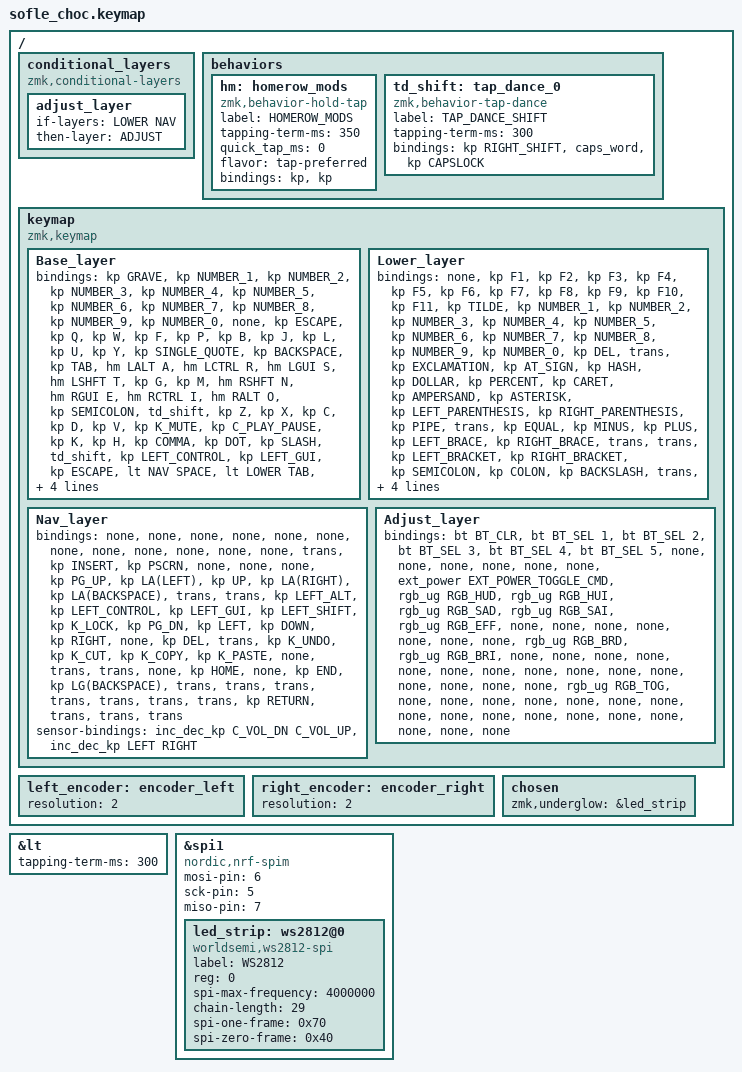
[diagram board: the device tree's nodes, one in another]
/*
 * Copyright (c) 2020 The ZMK Contributors
 *
 * SPDX-License-Identifier: MIT
 */

#include <behaviors.dtsi>
#include <dt-bindings/zmk/keys.h>
#include <dt-bindings/zmk/bt.h>
#include <dt-bindings/zmk/rgb.h>
#include <dt-bindings/zmk/ext_power.h>

#define BASE 0
#define LOWER 1
#define NAV 2
#define ADJUST 3

/*
 * Increase layer tap time
 */
&lt {
    tapping-term-ms = <300>;
};


/ {

  /*
   * Activate adjust layer by pressing raise and lower
   */

  conditional_layers {
      compatible = "zmk,conditional-layers";
      adjust_layer {
          if-layers = <LOWER NAV>;
          then-layer = <ADJUST>;
      };
  };


  /*
   * Homerow Mods config
   */

  behaviors {
    hm: homerow_mods {
      compatible = "zmk,behavior-hold-tap";
      label = "HOMEROW_MODS";
      #binding-cells = <2>;
      tapping-term-ms = <350>;
      quick_tap_ms = <0>;
      flavor = "tap-preferred";
      bindings = <&kp>, <&kp>;
    };

    td_shift: tap_dance_0 {
        compatible = "zmk,behavior-tap-dance";
        label = "TAP_DANCE_SHIFT";
        #binding-cells = <0>;
        tapping-term-ms = <300>;
        bindings = <&kp RIGHT_SHIFT>, <&caps_word>, <&kp CAPSLOCK>;
    };

  };

  /*
   * Keymap generated using https://www.keymapper.dev/
   * Import sofle_choc_keymap.json to view it.
   */

  keymap {
    compatible = "zmk,keymap";

    Base_layer {
      bindings = <
        &kp GRAVE &kp NUMBER_1 &kp NUMBER_2 &kp NUMBER_3 &kp NUMBER_4 &kp NUMBER_5 &kp NUMBER_6 &kp NUMBER_7 &kp NUMBER_8 &kp NUMBER_9 &kp NUMBER_0 &none &kp ESCAPE &kp Q &kp W &kp F &kp P &kp B &kp J &kp L &kp U &kp Y &kp SINGLE_QUOTE &kp BACKSPACE &kp TAB &hm LALT A &hm LCTRL R &hm LGUI S &hm LSHFT T &kp G &kp M &hm RSHFT N &hm RGUI E &hm RCTRL I &hm RALT O &kp SEMICOLON &td_shift &kp Z &kp X &kp C &kp D &kp V &kp K_MUTE &kp C_PLAY_PAUSE &kp K &kp H &kp COMMA &kp DOT &kp SLASH &td_shift &kp LEFT_CONTROL &kp LEFT_GUI &kp ESCAPE &lt NAV SPACE &lt LOWER TAB &lt LOWER LA(BACKSPACE) &lt NAV RETURN &td_shift &kp RIGHT_GUI &kp RIGHT_CONTROL
      >;
      sensor-bindings = <&inc_dec_kp C_VOL_DN C_VOL_UP &inc_dec_kp C_PREV C_NEXT>;
    };

    Lower_layer {
      bindings = <
        &none &kp F1 &kp F2 &kp F3 &kp F4 &kp F5 &kp F6 &kp F7 &kp F8 &kp F9 &kp F10 &kp F11 &kp TILDE &kp NUMBER_1 &kp NUMBER_2 &kp NUMBER_3 &kp NUMBER_4 &kp NUMBER_5 &kp NUMBER_6 &kp NUMBER_7 &kp NUMBER_8 &kp NUMBER_9 &kp NUMBER_0 &kp DEL &trans &kp EXCLAMATION &kp AT_SIGN &kp HASH &kp DOLLAR &kp PERCENT &kp CARET &kp AMPERSAND &kp ASTERISK &kp LEFT_PARENTHESIS &kp RIGHT_PARENTHESIS &kp PIPE &trans &kp EQUAL &kp MINUS &kp PLUS &kp LEFT_BRACE &kp RIGHT_BRACE &trans &trans &kp LEFT_BRACKET &kp RIGHT_BRACKET &kp SEMICOLON &kp COLON &kp BACKSLASH &trans &trans &trans &trans &trans &trans &kp DEL &trans &trans &trans &trans
      >;
      sensor-bindings = <&inc_dec_kp C_VOL_DN C_VOL_UP &inc_dec_kp LEFT RIGHT>;
    };

    Nav_layer {
      bindings = <
        &none &none &none &none &none &none &none &none &none &none &none &none &trans &kp INSERT &kp PSCRN &none &none &none &kp PG_UP &kp LA(LEFT) &kp UP &kp LA(RIGHT) &kp LA(BACKSPACE) &trans &trans &kp LEFT_ALT &kp LEFT_CONTROL &kp LEFT_GUI &kp LEFT_SHIFT &kp K_LOCK &kp PG_DN &kp LEFT &kp DOWN &kp RIGHT &none &kp DEL &trans &kp K_UNDO &kp K_CUT &kp K_COPY &kp K_PASTE &none &trans &trans &none &kp HOME &none &kp END &kp LG(BACKSPACE) &trans &trans &trans &trans &trans &trans &trans &kp RETURN &trans &trans &trans
      >;
      sensor-bindings = <&inc_dec_kp C_VOL_DN C_VOL_UP &inc_dec_kp LEFT RIGHT>;
    };

    Adjust_layer {
      bindings = <
        &bt BT_CLR &bt BT_SEL 1 &bt BT_SEL 2 &bt BT_SEL 3 &bt BT_SEL 4 &bt BT_SEL 5 &none &none &none &none &none &none &ext_power EXT_POWER_TOGGLE_CMD &rgb_ug RGB_HUD &rgb_ug RGB_HUI &rgb_ug RGB_SAD &rgb_ug RGB_SAI &rgb_ug RGB_EFF &none &none &none &none &none &none &none &rgb_ug RGB_BRD &rgb_ug RGB_BRI &none &none &none &none &none &none &none &none &none &none &none &none &none &none &none &rgb_ug RGB_TOG &none &none &none &none &none &none &none &none &none &none &none &none &none &none &none &none &none
      >;
    };
  };

  /*
   * Make encoders more sensitive
   */

  left_encoder: encoder_left {
      resolution = <2>;
  };

  right_encoder: encoder_right {
      resolution = <2>;
  };
};


/*
 * Temporarily here because nice nano v2 spi is not defined on ZMk Yet
 * Source: https://github.com/zmkfirmware/zmk/blob/main/app/boards/shields/reviung41/boards/nice_nano.overlay
 * GitHub Issue: https://github.com/zmkfirmware/zmk/issues/885
 */

&spi1 {
   compatible = "nordic,nrf-spim";
   status = "okay";
   mosi-pin = <6>;
   // Unused pins, needed for SPI definition, but not used by the ws2812 driver itself.
   sck-pin = <5>;
   miso-pin = <7>;

   led_strip: ws2812@0 {
      compatible = "worldsemi,ws2812-spi";
      label = "WS2812";

      /* SPI */
      reg = <0>; /* ignored, but necessary for SPI bindings */
      spi-max-frequency = <4000000>;

      /* WS2812 */
      chain-length = <29>; /* arbitrary; change at will */
      spi-one-frame = <0x70>;
      spi-zero-frame = <0x40>;
   };
};

/ {
   chosen {
      zmk,underglow = &led_strip;
   };
};
